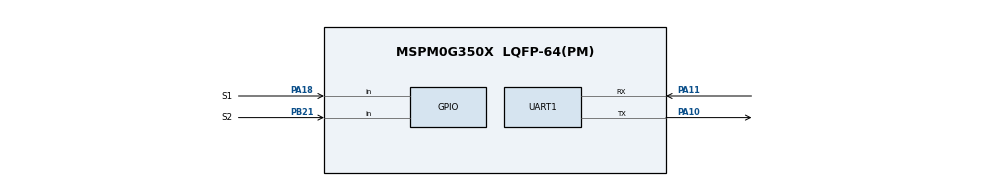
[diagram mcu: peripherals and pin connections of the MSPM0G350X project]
/**
 * @cliArgs --device "MSPM0G350X" --part "Default" --package "LQFP-64(PM)" --product "mspm0_sdk@2.03.00.08"
 * @versions {"tool":"1.21.2+3837"}
 */
// @cliArgs --board /ti/boards/LP_MSPM0G3507 --rtos nortos

/**
 * Import the modules used in this configuration.
 */
const GPIO   = scripting.addModule("/ti/driverlib/GPIO", {}, false);
const GPIO1  = GPIO.addInstance();
const GPIO2  = GPIO.addInstance();
const SYSCTL = scripting.addModule("/ti/driverlib/SYSCTL");
const UART   = scripting.addModule("/ti/driverlib/UART", {}, false);
const UART1  = UART.addInstance();

/**
 * Write custom configuration values to the imported modules.
 */
GPIO1.$name                          = "GPIO_LEDS";
GPIO1.associatedPins[0].assignedPort = "PORTA";
GPIO1.associatedPins[0].assignedPin  = "0";
GPIO1.associatedPins[0].initialValue = "SET";
GPIO1.associatedPins[0].$name        = "USER_LED_1";

const Board = scripting.addModule("/ti/driverlib/Board", {}, false);

GPIO2.$name                         = "GPIO_Switches";
GPIO2.associatedPins.create(2);
GPIO2.associatedPins[0].$name       = "S1";
GPIO2.associatedPins[0].direction   = "INPUT";
GPIO2.associatedPins[0].interruptEn = true;
GPIO2.associatedPins[0].polarity    = "RISE";
GPIO2.associatedPins[0].pin.$assign = "PA18";
GPIO2.associatedPins[1].$name       = "S2";
GPIO2.associatedPins[1].direction   = "INPUT";
GPIO2.associatedPins[1].interruptEn = true;
GPIO2.associatedPins[1].polarity    = "FALL";
GPIO2.associatedPins[1].pin.$assign = "PB21";

SYSCTL.forceDefaultClkConfig = true;
SYSCTL.clockTreeEn           = true;

UART1.$name                    = "UART_0";
UART1.enableFIFO               = true;
UART1.enableDMARX              = false;
UART1.enableDMATX              = false;
UART1.parity                   = "ODD";
UART1.rxFifoThreshold          = "DL_UART_RX_FIFO_LEVEL_ONE_ENTRY";
UART1.txFifoThreshold          = "DL_UART_TX_FIFO_LEVEL_3_4_EMPTY";
UART1.enabledInterrupts        = ["RX"];
UART1.targetBaudRate           = 250000;
UART1.peripheral.$assign       = "UART0";
UART1.peripheral.rxPin.$assign = "PA11";
UART1.peripheral.txPin.$assign = "PA10";
UART1.txPinConfig.$name        = "ti_driverlib_gpio_GPIOPinGeneric0";
UART1.txPinConfig.enableConfig = true;
UART1.txPinConfig.hiZ          = "ENABLE";
UART1.rxPinConfig.$name        = "ti_driverlib_gpio_GPIOPinGeneric1";

/**
 * Pinmux solution for unlocked pins/peripherals. This ensures that minor changes to the automatic solver in a future
 * version of the tool will not impact the pinmux you originally saw.  These lines can be completely deleted in order to
 * re-solve from scratch.
 */
GPIO1.associatedPins[0].pin.$suggestSolution = "PA0";
Board.peripheral.$suggestSolution            = "DEBUGSS";
Board.peripheral.swclkPin.$suggestSolution   = "PA20";
Board.peripheral.swdioPin.$suggestSolution   = "PA19";
